# Cortex-M0+ register map
Vendor: ARM Ltd.
Cortex-M0+ core descriptions, generated from ARM develloper studio
CPU: Cortex-M0+ r0p0, little endian, MPU, VTOR, vendor SysTick, 8 interrupt priority bits
Registers are 32-bit, read-write, no defined reset value unless marked. A register's access mark holds for its fields unless they carry their own. Offsets are from the block's base; lines under a group give offsets from that group; [hi:lo] are bit positions; {n}, {i} and the like mark numbered series; 'fields as' and 'values as' point back to an identical list; <NAME> marks a mode.

## Memory map
? SysTick size 0x80 — System Timer registers
? Control size 0xE0 — System Control registers
? ID size 0x20 — ID registers
? MPU size 0xA0 — Memory Protection Unit registers
? NVIC size 0x1A0 — Nested Vectored Interrupt Controller registers

## SysTick — System Timer registers
Base ?
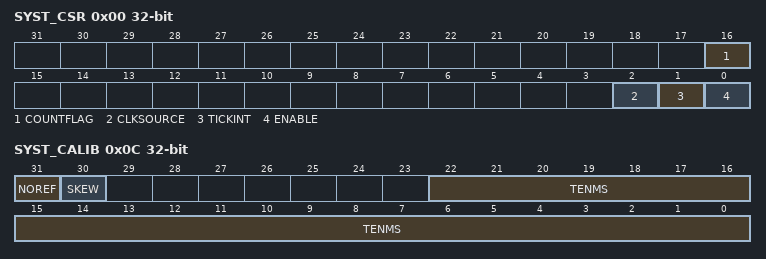
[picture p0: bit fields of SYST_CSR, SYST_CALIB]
0x00 SYST_CSR
  [16] COUNTFLAG — Indicates whether the counter has counted to 0 since the last read of this register
  [2] CLKSOURCE — Indicates the SysTick clock source
  [1] TICKINT — Indicates whether counting to 0 causes the status of the SysTick exception to change to pending
  [0] ENABLE — Indicates the enabled status of the SysTick counter
0x04 SYST_RVR
  [22:0] RELOAD — The value to load into the SYST_CVR register when the counter reaches 0
0x08 SYST_CVR
  [22:0] CURRENT — This is the value of the counter at the time it is sampled
0x0C SYST_CALIB
  [31] NOREF — Indicates whether the IMPLEMENTATION DEFINED reference clock is provided
  [30] SKEW — Indicates whether the 10ms calibration value is exact
  [22:0] TENMS — Optionally, holds a reload value to be used for 10ms (100Hz) timing, subject to system clock skew errors

## Control — System Control registers
Base ?
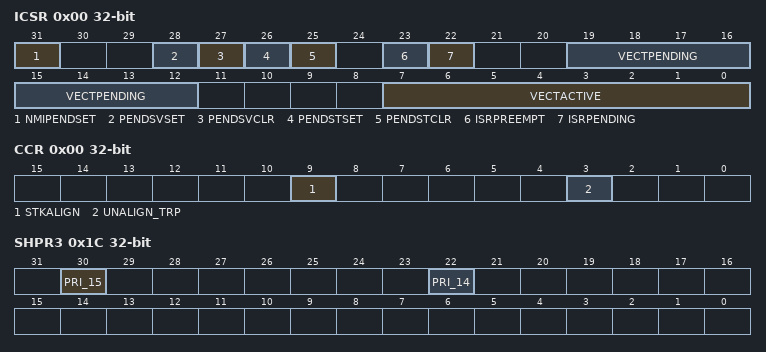
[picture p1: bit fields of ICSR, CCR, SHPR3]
0x00 ICSR
  [31] NMIPENDSET — Activates an NMI exception or reads back the current state
  [28] PENDSVSET — Sets a pending PendSV interrupt or reads back the current state
  [27] PENDSVCLR — Clears a pending PendSV interrupt
  [26] PENDSTSET — Sets a pending SysTick or reads back the current state
  [25] PENDSTCLR — Clears a pending SysTick, whether set here or by the timer hardware
  [23] ISRPREEMPT — Indicates whether a pending exception will be serviced on exit from debug halt state
  [22] ISRPENDING — Indicates if an external configurable, NVIC generated, interrupt is pending
  [19:12] VECTPENDING — The exception number for the highest priority pending exception. 0 indicates no pending exceptions
  [7:0] VECTACTIVE — The exception number for the current executing exception
0x00 CCR ro
  [9] STKALIGN — On exception entry, the SP used prior to the exception is adjusted to be 8-byte aligned and the context to restore it is saved. The SP is restored on the associated exception return
  [3] UNALIGN_TRP — Unaligned word and halfword accesses generate a HardFault exception
0x04 VTOR
  [29] TBLBASE — Determines whether the vector table is in the code or SRAM memory region
  [30:7] TBLOFF — Bits [31:7] of the vector table address
0x08 AIRCR
  [30:16] VECTKEY — Vector Key
  [30:16] VECTKEYSTAT
  [15] ENDIANNESS — Indicates the memory system data endianness
  [2] SYSRESETREQ — System Reset Request
  [1] VECTCLRACTIVE — Clears all active state information for fixed and configurable exceptions
0x18 SHPR2
  [30] PRI_11 — Priority of system handler 11, SVCall
0x1C SHPR3
  [30] PRI_15 — Priority of system handler 15, SysTick
  [22] PRI_14 — Priority of system handler 14, PendSV
0x20 SHCSR
  [15] SVCALLPENDED — This bit reflects the pending state on a read, and updates the pending state, to the value written, on a write

## ID — ID registers
Base ?
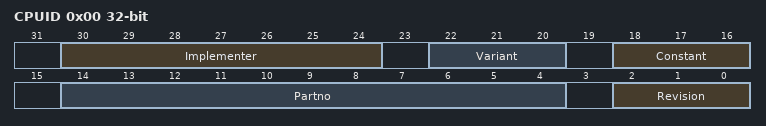
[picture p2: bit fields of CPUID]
0x00 CPUID ro
  [30:24] Implementer — Implementer code
  [22:20] Variant — Implementation defined
  [18:16] Constant — Indicates the architecture
  [14:4] Partno — Indicates part number
  [2:0] Revision — Indicates revision

## MPU — Memory Protection Unit registers
Base ?
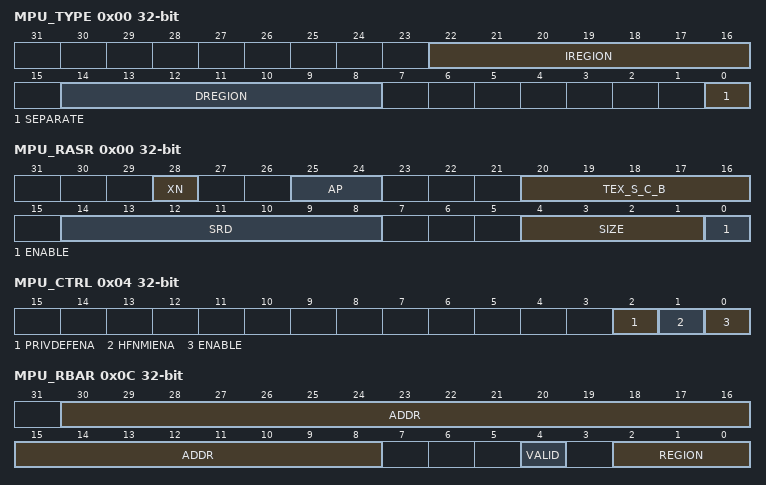
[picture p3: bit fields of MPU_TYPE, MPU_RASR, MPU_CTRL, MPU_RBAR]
0x00 MPU_TYPE ro
  [22:16] IREGION — Instruction region, not supported
  [14:8] DREGION — Number of regions supported by the MPU
  [0] SEPARATE — Indicates support for separate instruction and data address maps
0x00 MPU_RASR
  [28] XN — Execute Never - Indicates whether the processor can execute instructions from the region
  [25:24] AP — Access and privilege properties of the region
  [20:16] TEX_S_C_B — Memory type, cacheable and shareable properties of the region
  [14:8] SRD — Subregion Disable
  [4:1] SIZE — Indicates the region size
  [0] ENABLE — Enables this region (when the MPU is enabled)
0x04 MPU_CTRL
  [2] PRIVDEFENA — Privileged default memory map enable (when ENABLE = 1)
  [1] HFNMIENA — MPU HardFault and NMI enable (when ENABLE = 1)
  [0] ENABLE — Enables the MPU
0x08 MPU_RNR
  [6:0] REGION — Indicates the memory region accessed by MPU_RBAR and MPU_RASR
0x0C MPU_RBAR
  [30:8] ADDR — Base address of the region
  [4] VALID — On writes to the register, indicates whether the write must update the base address of the region identified by the REGION field
  [2:0] REGION — On writes, can specify the number of the region to update, on reads, returns bits [3:0] of MPU_RNR

## NVIC — Nested Vectored Interrupt Controller registers
Base ?
0x00 NVIC_ISER0
0x00 NVIC_ISPR0
0x80 NVIC_ICER0
0x180 NVIC_ICPR0
0x200 NVIC_IABR0
{0x300+4i} NVIC_IPR{i} (i=0..7)
